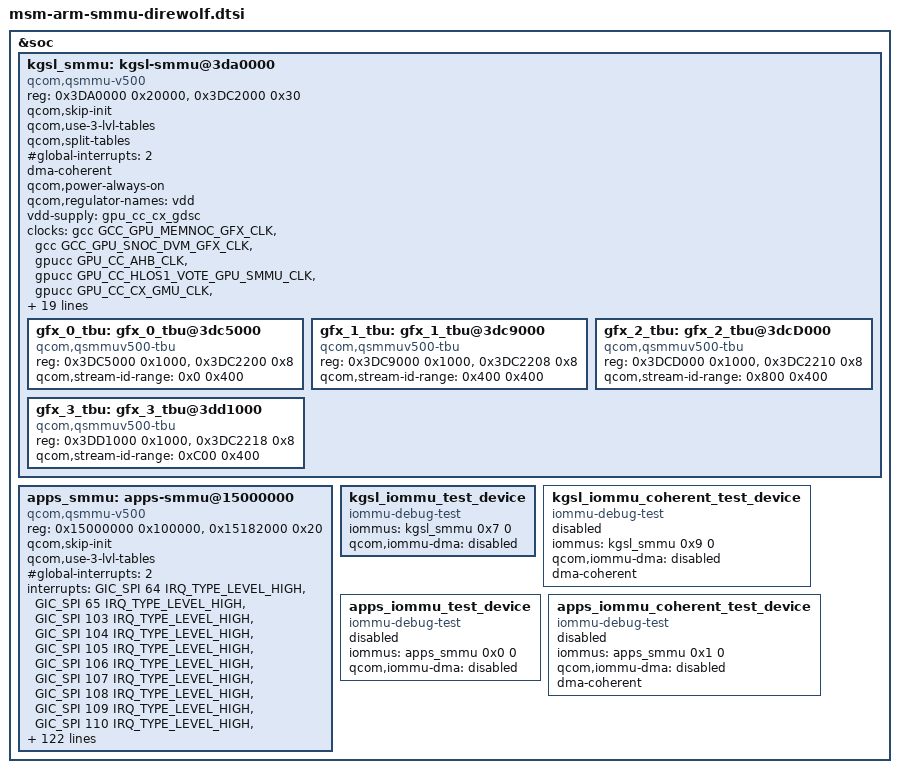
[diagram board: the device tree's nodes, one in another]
#include <dt-bindings/interrupt-controller/arm-gic.h>

&soc {
	kgsl_smmu: kgsl-smmu@3da0000 {
		compatible = "qcom,qsmmu-v500";
		reg = <0x3DA0000 0x20000>,
			<0x3DC2000 0x30>;
		reg-names = "base", "tcu-base";
		#iommu-cells = <2>;
		qcom,skip-init;
		qcom,use-3-lvl-tables;
		qcom,split-tables;
		#global-interrupts = <2>;
		#size-cells = <1>;
		#address-cells = <1>;
		ranges;
		dma-coherent;
		qcom,power-always-on;
		qcom,regulator-names = "vdd";
		vdd-supply = <&gpu_cc_cx_gdsc>;

		clocks = <&gcc GCC_GPU_MEMNOC_GFX_CLK>,
			 <&gcc GCC_GPU_SNOC_DVM_GFX_CLK>,
			 <&gpucc GPU_CC_AHB_CLK>,
			 <&gpucc GPU_CC_HLOS1_VOTE_GPU_SMMU_CLK>,
			 <&gpucc GPU_CC_CX_GMU_CLK>,
			 <&gpucc GPU_CC_HUB_CX_INT_CLK>,
			 <&gpucc GPU_CC_HUB_AON_CLK>;

		clock-names = "gcc_gpu_memnoc_gfx",
			      "gcc_gpu_snoc_dvm_gfx",
			      "gpu_cc_ahb",
			      "gpu_cc_hlos1_vote_gpu_smmu_clk",
			      "gpu_cc_cx_gmu_clk",
			      "gpu_cc_hub_cx_int_clk",
			      "gpu_cc_hub_aon_clk";

		qcom,actlr =
			/* All CBs of GFX: +15 deep PF */
			<0x0 0xc00 0x32B>,
			<0x1 0xc00 0x32B>,
			<0x2 0xc00 0x32B>,
			<0x4 0xc00 0x32B>,
			<0x5 0xc00 0x32B>,
			<0x7 0xc00 0x32B>;

		interrupts =	<GIC_SPI 672 IRQ_TYPE_LEVEL_HIGH>,
				<GIC_SPI 673 IRQ_TYPE_LEVEL_HIGH>,
				<GIC_SPI 678 IRQ_TYPE_LEVEL_HIGH>,

				<GIC_SPI 679 IRQ_TYPE_LEVEL_HIGH>,
				<GIC_SPI 680 IRQ_TYPE_LEVEL_HIGH>,

				<GIC_SPI 681 IRQ_TYPE_LEVEL_HIGH>,
				<GIC_SPI 682 IRQ_TYPE_LEVEL_HIGH>,
				<GIC_SPI 683 IRQ_TYPE_LEVEL_HIGH>,
				<GIC_SPI 684 IRQ_TYPE_LEVEL_HIGH>,
				<GIC_SPI 685 IRQ_TYPE_LEVEL_HIGH>,
				<GIC_SPI 686 IRQ_TYPE_LEVEL_HIGH>,
				<GIC_SPI 687 IRQ_TYPE_LEVEL_HIGH>,
				<GIC_SPI 688 IRQ_TYPE_LEVEL_HIGH>,
				<GIC_SPI 689 IRQ_TYPE_LEVEL_HIGH>;

		gfx_0_tbu: gfx_0_tbu@3dc5000 {
			compatible = "qcom,qsmmuv500-tbu";
			reg = <0x3DC5000 0x1000>,
				<0x3DC2200 0x8>;
			reg-names = "base", "status-reg";
			qcom,stream-id-range = <0x0 0x400>;
		};

		gfx_1_tbu: gfx_1_tbu@3dc9000 {
			compatible = "qcom,qsmmuv500-tbu";
			reg = <0x3DC9000 0x1000>,
				<0x3DC2208 0x8>;
			reg-names = "base", "status-reg";
			qcom,stream-id-range = <0x400 0x400>;
		};

		gfx_2_tbu: gfx_2_tbu@3dcD000 {
			compatible = "qcom,qsmmuv500-tbu";
			reg = <0x3DCD000 0x1000>,
				<0x3DC2210 0x8>;
			reg-names = "base", "status-reg";
			qcom,stream-id-range = <0x800 0x400>;
		};

		gfx_3_tbu: gfx_3_tbu@3dd1000 {
			compatible = "qcom,qsmmuv500-tbu";
			reg = <0x3DD1000 0x1000>,
				<0x3DC2218 0x8>;
			reg-names = "base", "status-reg";
			qcom,stream-id-range = <0xC00 0x400>;
		};
	};

	apps_smmu: apps-smmu@15000000 {
		compatible = "qcom,qsmmu-v500";
		reg = <0x15000000 0x100000>,
			<0x15182000 0x20>;
		reg-names = "base", "tcu-base";
		#iommu-cells = <2>;
		qcom,skip-init;
		qcom,use-3-lvl-tables;
		#global-interrupts = <2>;
		#size-cells = <1>;
		#address-cells = <1>;
		ranges;
		interrupts =	<GIC_SPI 64 IRQ_TYPE_LEVEL_HIGH>,
				<GIC_SPI 65 IRQ_TYPE_LEVEL_HIGH>,
				<GIC_SPI 103 IRQ_TYPE_LEVEL_HIGH>,
				<GIC_SPI 104 IRQ_TYPE_LEVEL_HIGH>,
				<GIC_SPI 105 IRQ_TYPE_LEVEL_HIGH>,
				<GIC_SPI 106 IRQ_TYPE_LEVEL_HIGH>,
				<GIC_SPI 107 IRQ_TYPE_LEVEL_HIGH>,
				<GIC_SPI 108 IRQ_TYPE_LEVEL_HIGH>,
				<GIC_SPI 109 IRQ_TYPE_LEVEL_HIGH>,
				<GIC_SPI 110 IRQ_TYPE_LEVEL_HIGH>,
				<GIC_SPI 111 IRQ_TYPE_LEVEL_HIGH>,
				<GIC_SPI 112 IRQ_TYPE_LEVEL_HIGH>,
				<GIC_SPI 113 IRQ_TYPE_LEVEL_HIGH>,
				<GIC_SPI 114 IRQ_TYPE_LEVEL_HIGH>,
				<GIC_SPI 115 IRQ_TYPE_LEVEL_HIGH>,
				<GIC_SPI 116 IRQ_TYPE_LEVEL_HIGH>,
				<GIC_SPI 117 IRQ_TYPE_LEVEL_HIGH>,
				<GIC_SPI 118 IRQ_TYPE_LEVEL_HIGH>,
				<GIC_SPI 181 IRQ_TYPE_LEVEL_HIGH>,
				<GIC_SPI 182 IRQ_TYPE_LEVEL_HIGH>,
				<GIC_SPI 183 IRQ_TYPE_LEVEL_HIGH>,
				<GIC_SPI 184 IRQ_TYPE_LEVEL_HIGH>,
				<GIC_SPI 185 IRQ_TYPE_LEVEL_HIGH>,
				<GIC_SPI 186 IRQ_TYPE_LEVEL_HIGH>,
				<GIC_SPI 187 IRQ_TYPE_LEVEL_HIGH>,
				<GIC_SPI 188 IRQ_TYPE_LEVEL_HIGH>,
				<GIC_SPI 189 IRQ_TYPE_LEVEL_HIGH>,
				<GIC_SPI 190 IRQ_TYPE_LEVEL_HIGH>,
				<GIC_SPI 191 IRQ_TYPE_LEVEL_HIGH>,
				<GIC_SPI 192 IRQ_TYPE_LEVEL_HIGH>,
				<GIC_SPI 315 IRQ_TYPE_LEVEL_HIGH>,
				<GIC_SPI 316 IRQ_TYPE_LEVEL_HIGH>,
				<GIC_SPI 317 IRQ_TYPE_LEVEL_HIGH>,
				<GIC_SPI 318 IRQ_TYPE_LEVEL_HIGH>,
				<GIC_SPI 319 IRQ_TYPE_LEVEL_HIGH>,
				<GIC_SPI 320 IRQ_TYPE_LEVEL_HIGH>,
				<GIC_SPI 321 IRQ_TYPE_LEVEL_HIGH>,
				<GIC_SPI 322 IRQ_TYPE_LEVEL_HIGH>,
				<GIC_SPI 323 IRQ_TYPE_LEVEL_HIGH>,
				<GIC_SPI 324 IRQ_TYPE_LEVEL_HIGH>,
				<GIC_SPI 325 IRQ_TYPE_LEVEL_HIGH>,
				<GIC_SPI 326 IRQ_TYPE_LEVEL_HIGH>,
				<GIC_SPI 327 IRQ_TYPE_LEVEL_HIGH>,
				<GIC_SPI 328 IRQ_TYPE_LEVEL_HIGH>,
				<GIC_SPI 329 IRQ_TYPE_LEVEL_HIGH>,
				<GIC_SPI 330 IRQ_TYPE_LEVEL_HIGH>,
				<GIC_SPI 331 IRQ_TYPE_LEVEL_HIGH>,
				<GIC_SPI 332 IRQ_TYPE_LEVEL_HIGH>,
				<GIC_SPI 333 IRQ_TYPE_LEVEL_HIGH>,
				<GIC_SPI 334 IRQ_TYPE_LEVEL_HIGH>,
				<GIC_SPI 335 IRQ_TYPE_LEVEL_HIGH>,
				<GIC_SPI 336 IRQ_TYPE_LEVEL_HIGH>,
				<GIC_SPI 337 IRQ_TYPE_LEVEL_HIGH>,
				<GIC_SPI 338 IRQ_TYPE_LEVEL_HIGH>,
				<GIC_SPI 339 IRQ_TYPE_LEVEL_HIGH>,
				<GIC_SPI 340 IRQ_TYPE_LEVEL_HIGH>,
				<GIC_SPI 341 IRQ_TYPE_LEVEL_HIGH>,
				<GIC_SPI 342 IRQ_TYPE_LEVEL_HIGH>,
				<GIC_SPI 343 IRQ_TYPE_LEVEL_HIGH>,
				<GIC_SPI 344 IRQ_TYPE_LEVEL_HIGH>,
				<GIC_SPI 345 IRQ_TYPE_LEVEL_HIGH>,
				<GIC_SPI 395 IRQ_TYPE_LEVEL_HIGH>,
				<GIC_SPI 396 IRQ_TYPE_LEVEL_HIGH>,
				<GIC_SPI 397 IRQ_TYPE_LEVEL_HIGH>,
				<GIC_SPI 398 IRQ_TYPE_LEVEL_HIGH>,
				<GIC_SPI 399 IRQ_TYPE_LEVEL_HIGH>,
				<GIC_SPI 400 IRQ_TYPE_LEVEL_HIGH>,
				<GIC_SPI 401 IRQ_TYPE_LEVEL_HIGH>,
				<GIC_SPI 402 IRQ_TYPE_LEVEL_HIGH>,
				<GIC_SPI 403 IRQ_TYPE_LEVEL_HIGH>,
				<GIC_SPI 404 IRQ_TYPE_LEVEL_HIGH>,
				<GIC_SPI 405 IRQ_TYPE_LEVEL_HIGH>,
				<GIC_SPI 406 IRQ_TYPE_LEVEL_HIGH>,
				<GIC_SPI 407 IRQ_TYPE_LEVEL_HIGH>,
				<GIC_SPI 408 IRQ_TYPE_LEVEL_HIGH>,
				<GIC_SPI 409 IRQ_TYPE_LEVEL_HIGH>,
				<GIC_SPI 418 IRQ_TYPE_LEVEL_HIGH>,
				<GIC_SPI 419 IRQ_TYPE_LEVEL_HIGH>,
				<GIC_SPI 412 IRQ_TYPE_LEVEL_HIGH>,
				<GIC_SPI 421 IRQ_TYPE_LEVEL_HIGH>,
				<GIC_SPI 706 IRQ_TYPE_LEVEL_HIGH>,
				<GIC_SPI 423 IRQ_TYPE_LEVEL_HIGH>,
				<GIC_SPI 424 IRQ_TYPE_LEVEL_HIGH>,
				<GIC_SPI 425 IRQ_TYPE_LEVEL_HIGH>,
				<GIC_SPI 689 IRQ_TYPE_LEVEL_HIGH>,
				<GIC_SPI 690 IRQ_TYPE_LEVEL_HIGH>,
				<GIC_SPI 691 IRQ_TYPE_LEVEL_HIGH>,
				<GIC_SPI 692 IRQ_TYPE_LEVEL_HIGH>,
				<GIC_SPI 693 IRQ_TYPE_LEVEL_HIGH>,
				<GIC_SPI 694 IRQ_TYPE_LEVEL_HIGH>,
				<GIC_SPI 695 IRQ_TYPE_LEVEL_HIGH>,
				<GIC_SPI 696 IRQ_TYPE_LEVEL_HIGH>,
				<GIC_SPI 410 IRQ_TYPE_LEVEL_HIGH>,
				<GIC_SPI 411 IRQ_TYPE_LEVEL_HIGH>,
				<GIC_SPI 420 IRQ_TYPE_LEVEL_HIGH>,
				<GIC_SPI 413 IRQ_TYPE_LEVEL_HIGH>,
				<GIC_SPI 422 IRQ_TYPE_LEVEL_HIGH>,
				<GIC_SPI 707 IRQ_TYPE_LEVEL_HIGH>,
				<GIC_SPI 708 IRQ_TYPE_LEVEL_HIGH>,
				<GIC_SPI 709 IRQ_TYPE_LEVEL_HIGH>,
				<GIC_SPI 710 IRQ_TYPE_LEVEL_HIGH>,
				<GIC_SPI 711 IRQ_TYPE_LEVEL_HIGH>,
				<GIC_SPI 414 IRQ_TYPE_LEVEL_HIGH>,
				<GIC_SPI 712 IRQ_TYPE_LEVEL_HIGH>,
				<GIC_SPI 713 IRQ_TYPE_LEVEL_HIGH>,
				<GIC_SPI 714 IRQ_TYPE_LEVEL_HIGH>,
				<GIC_SPI 715 IRQ_TYPE_LEVEL_HIGH>,
				<GIC_SPI 912 IRQ_TYPE_LEVEL_HIGH>,
				<GIC_SPI 911 IRQ_TYPE_LEVEL_HIGH>,
				<GIC_SPI 910 IRQ_TYPE_LEVEL_HIGH>,
				<GIC_SPI 909 IRQ_TYPE_LEVEL_HIGH>,
				<GIC_SPI 908 IRQ_TYPE_LEVEL_HIGH>,
				<GIC_SPI 907 IRQ_TYPE_LEVEL_HIGH>,
				<GIC_SPI 906 IRQ_TYPE_LEVEL_HIGH>,
				<GIC_SPI 905 IRQ_TYPE_LEVEL_HIGH>,
				<GIC_SPI 904 IRQ_TYPE_LEVEL_HIGH>,
				<GIC_SPI 903 IRQ_TYPE_LEVEL_HIGH>,
				<GIC_SPI 902 IRQ_TYPE_LEVEL_HIGH>,
				<GIC_SPI 901 IRQ_TYPE_LEVEL_HIGH>,
				<GIC_SPI 900 IRQ_TYPE_LEVEL_HIGH>,
				<GIC_SPI 899 IRQ_TYPE_LEVEL_HIGH>,
				<GIC_SPI 898 IRQ_TYPE_LEVEL_HIGH>,
				<GIC_SPI 897 IRQ_TYPE_LEVEL_HIGH>,
				<GIC_SPI 896 IRQ_TYPE_LEVEL_HIGH>,
				<GIC_SPI 895 IRQ_TYPE_LEVEL_HIGH>,
				<GIC_SPI 894 IRQ_TYPE_LEVEL_HIGH>,
				<GIC_SPI 893 IRQ_TYPE_LEVEL_HIGH>,
				<GIC_SPI 892 IRQ_TYPE_LEVEL_HIGH>,
				<GIC_SPI 891 IRQ_TYPE_LEVEL_HIGH>,
				<GIC_SPI 890 IRQ_TYPE_LEVEL_HIGH>;

		interconnects = <&gem_noc MASTER_APPSS_PROC
				&config_noc SLAVE_IMEM_CFG>;
	};

	kgsl_iommu_test_device {
		compatible = "iommu-debug-test";
		iommus = <&kgsl_smmu 0x7 0>;
		qcom,iommu-dma = "disabled";
	};

	kgsl_iommu_coherent_test_device {
		status = "disabled";
		compatible = "iommu-debug-test";
		iommus = <&kgsl_smmu 0x9 0>;
		qcom,iommu-dma = "disabled";
		dma-coherent;
	};

	apps_iommu_test_device {
		compatible = "iommu-debug-test";
		iommus = <&apps_smmu 0x0 0>;
		qcom,iommu-dma = "disabled";
		status = "disabled";
	};

	apps_iommu_coherent_test_device {
		compatible = "iommu-debug-test";
		iommus = <&apps_smmu 0x1 0>;
		qcom,iommu-dma = "disabled";
		dma-coherent;
		status = "disabled";
	};
};
